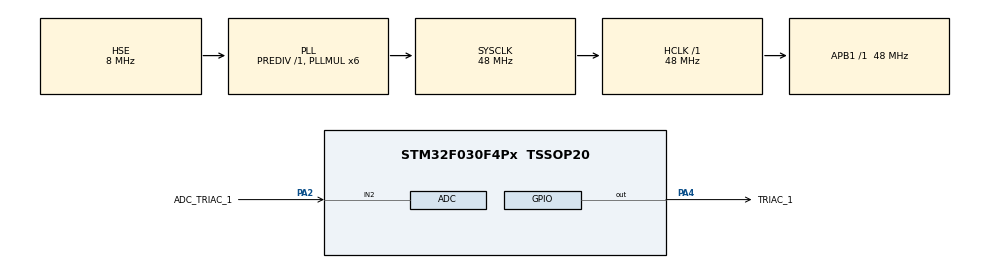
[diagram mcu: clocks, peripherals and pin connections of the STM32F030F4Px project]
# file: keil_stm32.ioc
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ADC.ClockPrescaler=ADC_CLOCK_ASYNC_DIV1
ADC.ContinuousConvMode=DISABLE
ADC.DMAContinuousRequests=DISABLE
ADC.DataAlign=ADC_DATAALIGN_RIGHT
ADC.DiscontinuousConvMode=DISABLE
ADC.EOCSelection=ADC_EOC_SINGLE_CONV
ADC.EnableAnalogWatchDog=false
ADC.ExternalTrigConv=ADC_SOFTWARE_START
ADC.ExternalTrigConvEdge=ADC_EXTERNALTRIGCONVEDGE_NONE
ADC.LowPowerAutoPowerOff=DISABLE
ADC.LowPowerAutoWait=DISABLE
ADC.Overrun=ADC_OVR_DATA_PRESERVED
ADC.Resolution=ADC_RESOLUTION_12B
ADC.SamplingTime=ADC_SAMPLETIME_7CYCLES_5
ADC.ScanConvMode=ADC_SCAN_DIRECTION_FORWARD
Dma.ADC.0.Direction=DMA_PERIPH_TO_MEMORY
Dma.ADC.0.Instance=DMA1_Channel1
Dma.ADC.0.MemDataAlignment=DMA_MDATAALIGN_HALFWORD
Dma.ADC.0.MemInc=DMA_MINC_ENABLE
Dma.ADC.0.Mode=DMA_NORMAL
Dma.ADC.0.PeriphDataAlignment=DMA_PDATAALIGN_HALFWORD
Dma.ADC.0.PeriphInc=DMA_PINC_DISABLE
Dma.ADC.0.Priority=DMA_PRIORITY_VERY_HIGH
Dma.Request0=ADC
IWDG.Prescaler=IWDG_PRESCALER_16
IWDG.Reload=2500
Mcu.Family=STM32F0
Mcu.Name=STM32F030F4Px
Mcu.Package=TSSOP20
NVIC.ADC1_IRQn=true\:0\:0\:false\:false\:true\:true\:true
NVIC.DMA1_Channel1_IRQn=true\:0\:0\:false\:false\:true\:false\:true
NVIC.TIM1_BRK_UP_TRG_COM_IRQn=true\:0\:0\:false\:false\:true\:true\:true
NVIC.TIM1_CC_IRQn=true\:0\:0\:false\:false\:true\:true\:true
PA13.Mode=Serial_Wire
PA13.Signal=SYS_SWDIO
PA14.Mode=Serial_Wire
PA14.Signal=SYS_SWCLK
PA2.GPIO_Label=ADC_TRIAC_1
PA2.Mode=IN2
PA2.Signal=ADC_IN2
PA4.GPIO_Label=TRIAC_1
PA4.Signal=GPIO_Output
PF0-OSC_IN.Mode=HSE-External-Oscillator
PF0-OSC_IN.Signal=RCC_OSC_IN
PF1-OSC_OUT.Mode=HSE-External-Oscillator
PF1-OSC_OUT.Signal=RCC_OSC_OUT
ProjectManager.HeapSize=0x200
ProjectManager.StackSize=0x400
ProjectManager.TargetToolchain=MDK-ARM V5.27
RCC.AHBFreq_Value=48000000
RCC.APB1Freq_Value=48000000
RCC.APB1TimFreq_Value=48000000
RCC.HCLKFreq_Value=48000000
RCC.PLLMUL=RCC_PLL_MUL6
RCC.PLLSourceVirtual=RCC_PLLSOURCE_HSE
RCC.SYSCLKFreq_VALUE=48000000
RCC.SYSCLKSource=RCC_SYSCLKSOURCE_PLLCLK
TIM1.Period=9
TIM1.Prescaler=4799
VP_IWDG_VS_IWDG.Mode=IWDG_Activate
VP_TIM1_VS_ClockSourceINT.Mode=Internal
board=voltage_regulator_1_channel_v3_3

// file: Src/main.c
/* USER CODE BEGIN Header */
/**
  ******************************************************************************
  * @file           : main.c
  * @brief          : Main program body
  ******************************************************************************
  * @attention
  *
  * <h2><center>&copy; Copyright (c) 2022 STMicroelectronics.
  * All rights reserved.</center></h2>
  *
  * This software component is licensed by ST under BSD 3-Clause license,
  * the "License"; You may not use this file except in compliance with the
  * License. You may obtain a copy of the License at:
  *                        opensource.org/licenses/BSD-3-Clause
  *
  ******************************************************************************
  */
/* USER CODE END Header */
#include "main.h"
#include "adc.h"
#include "dma.h"
#include "iwdg.h"
#include "tim.h"
#include "gpio.h"

/* USER CODE BEGIN Includes */
#include <stdbool.h>
#include <stdint.h>

#include "ntc3950.h"
/* USER CODE END Includes */

/* USER CODE BEGIN PD */
#define SECONDS                   60      // 1 minute
#define M_SECONDS                 1000    // 1 second

#define ADC_MEASUREMENT_PERIOD    100     // us
#define ADC_MEASUREMENTS          100     // 100 * 100 us = 10 ms period between ADC averaged measurents

#define REGULATOR_NTC_FAULT       -123
/* USER CODE END PD */

/* USER CODE BEGIN PV */
static volatile uint32_t heat_up_timer = 0;
static uint8_t heat_up_time = 0;

static float set_temperature = 0.0;
static float cur_temperature = 0.0;

static volatile uint16_t adc_dma[1];
static volatile uint8_t adc_measurements = 0;
static volatile uint32_t adc_sum = 0;
static volatile uint16_t adc_avg = 0;

static volatile bool temp_sensor_fault = false;
static volatile bool temp_sensor_loose = false;
/* USER CODE END PV */

void SystemClock_Config(void);

/* USER CODE BEGIN 0 */
void HAL_ADC_ConvCpltCallback(ADC_HandleTypeDef *hadc)
{
  adc_sum += adc_dma[0];
  adc_measurements++;

  if (adc_measurements >= ADC_MEASUREMENTS)
  {
    adc_avg = adc_sum / adc_measurements;
    adc_measurements = 0;
    adc_sum = 0;
  }
}

void HAL_TIM_PeriodElapsedCallback(TIM_HandleTypeDef *htim)
{
  if (htim->Instance == TIM1) // 1 ms
  {
    heat_up_timer++;
  }
}

void read_temperature()
{
  cur_temperature = ntc3950_read_temperature(adc_avg);
  if (cur_temperature == REGULATOR_NTC_FAULT)
  {
    HAL_GPIO_WritePin(TRIAC_1_GPIO_Port, ADC_TRIAC_1_Pin, GPIO_PIN_SET);
    temp_sensor_fault = true;
  }
  else
  {
    if (round_float(cur_temperature) >= round_float(set_temperature) || heat_up_time == 0)
    {
      HAL_GPIO_WritePin(TRIAC_1_GPIO_Port, ADC_TRIAC_1_Pin, GPIO_PIN_RESET);
      temp_sensor_loose = false;
    }
    else if (heat_up_timer >= heat_up_time * SECONDS * M_SECONDS)
    {
      HAL_GPIO_WritePin(TRIAC_1_GPIO_Port, ADC_TRIAC_1_Pin, GPIO_PIN_SET);
      temp_sensor_loose = true;
      heat_up_timer = 0;
    }
  }
}
/* USER CODE END 0 */

int main(void)
{

  /* MCU Configuration--------------------------------------------------------*/

  /* Reset of all peripherals, Initializes the Flash interface and the Systick. */
  HAL_Init();

  /* USER CODE BEGIN Init */
  HAL_IWDG_Init(&hiwdg);

  HAL_TIM_Base_Start_IT(&htim1);
  /* USER CODE END Init */

  /* Configure the system clock */
  SystemClock_Config();

  /* Initialize all configured peripherals */
  MX_GPIO_Init();
  MX_DMA_Init();
  MX_ADC_Init();
  MX_IWDG_Init();
  MX_TIM1_Init();

  /* Infinite loop */
  while (1)
  {

    /* USER CODE BEGIN 3 */
    HAL_IWDG_Refresh(&hiwdg);

    read_temperature();
  }
  /* USER CODE END 3 */
}

void SystemClock_Config(void)
{
  RCC_OscInitTypeDef RCC_OscInitStruct = {0};
  RCC_ClkInitTypeDef RCC_ClkInitStruct = {0};

  /** Initializes the RCC Oscillators according to the specified parameters
  * in the RCC_OscInitTypeDef structure.
  */
  RCC_OscInitStruct.OscillatorType = RCC_OSCILLATORTYPE_HSI14|RCC_OSCILLATORTYPE_LSI
                              |RCC_OSCILLATORTYPE_HSE;
  RCC_OscInitStruct.HSEState = RCC_HSE_ON;
  RCC_OscInitStruct.HSI14State = RCC_HSI14_ON;
  RCC_OscInitStruct.HSI14CalibrationValue = 16;
  RCC_OscInitStruct.LSIState = RCC_LSI_ON;
  RCC_OscInitStruct.PLL.PLLState = RCC_PLL_ON;
  RCC_OscInitStruct.PLL.PLLSource = RCC_PLLSOURCE_HSE;
  RCC_OscInitStruct.PLL.PLLMUL = RCC_PLL_MUL6;
  RCC_OscInitStruct.PLL.PREDIV = RCC_PREDIV_DIV1;
  if (HAL_RCC_OscConfig(&RCC_OscInitStruct) != HAL_OK)
  {
    Error_Handler();
  }
  /** Initializes the CPU, AHB and APB buses clocks
  */
  RCC_ClkInitStruct.ClockType = RCC_CLOCKTYPE_HCLK|RCC_CLOCKTYPE_SYSCLK
                              |RCC_CLOCKTYPE_PCLK1;
  RCC_ClkInitStruct.SYSCLKSource = RCC_SYSCLKSOURCE_PLLCLK;
  RCC_ClkInitStruct.AHBCLKDivider = RCC_SYSCLK_DIV1;
  RCC_ClkInitStruct.APB1CLKDivider = RCC_HCLK_DIV1;

  if (HAL_RCC_ClockConfig(&RCC_ClkInitStruct, FLASH_LATENCY_1) != HAL_OK)
  {
    Error_Handler();
  }
}

void Error_Handler(void)
{
  __disable_irq();
  while (1)
  {
  }
}

/************************ (C) COPYRIGHT STMicroelectronics *****END OF FILE****/
